# AC78xx register map
Vendor: AutoChips; Series: AC78xx; File version: 1.0
CPU: CM3 r2p1, little endian, MPU, no FPU, 3 interrupt priority bits
Registers are 32-bit, read-write, no defined reset value unless marked. A register's access mark holds for its fields unless they carry their own. Offsets are from the block's base; [hi:lo] are bit positions; {n}, {i} and the like mark numbered series; 'fields as' and 'values as' point back to an identical list.

## PWM0 — Pulse Width Management Module
Base 0x40013000; register names take the prefix PWM0_
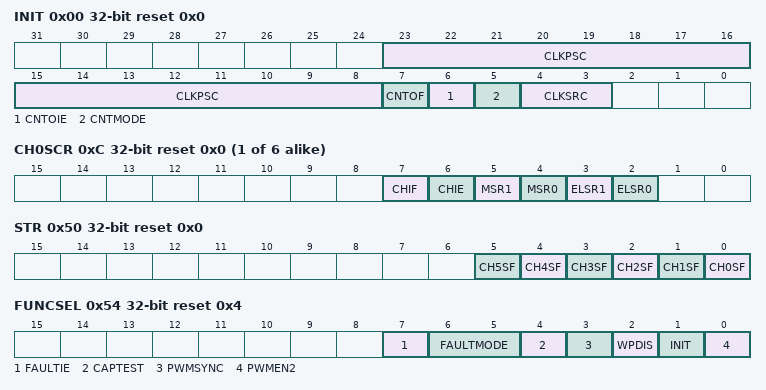
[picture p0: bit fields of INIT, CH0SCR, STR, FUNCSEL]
0x00 INIT reset 0x0 — PWM Initialize, Include Clock and Prescale Setting
  [23:8] CLKPSC — Prescale Factor Selection
  [7] CNTOF ro — PWM Counter Overflow Flag
    0=PWM counter has not overflowed; 1=PWM counter has overflowed
  [6] CNTOIE — PWM Counter Overflow Interrupt Enable
    0=Disable CNTOF interrupts. Use software polling.; 1=Enable CNTOF interrupts. An interrupt is generated when CNTOF equals one.
  [5] CNTMODE — PWM Counter Mode Select
    0=PWM counter operates in Up Counting mode; 1=PWM counter operates in Up-Down Counting mode
  [4:3] CLKSRC — Clock Source Selection
    0=No clock selected. This in effect disables the PWM counter.; 1=System clock; 2=Fixed frequency clock; 3=External clock
0x04 CNT reset 0x0 — PWM Counter Current Count Value
  [15:0] COUNT — Current Counter Value
0x08 MCVR reset 0x0 — PWM Counter Max Count Value Register
  [15:0] MCVR
{0xC+8i} CH{i}SCR (i=0..5) reset 0x0 — Channel (n) Status And Control Register
  [7] CHIF ro — Channel Interrupt Flag
    0=No channel event has occurred; 1=A channel event has occurred
  [6] CHIE — Channel Interrupt Enable
    0=Disable channel interrupts. Use software polling.; 1=Enable channel interrupts
  [5] MSR1 — Channel Mode Select Register 1
  [4] MSR0 — Channel Mode Select Register 0
  [3] ELSR1 — Edge or Level Select Register 1
  [2] ELSR0 — Edge or Level Select Register 0
{0x10+8i} CH{i}V (i=0..5) reset 0x0 — Channel (n) Value
  [15:0] CHCVAL — Channel Count Value
0x4C CNTIN reset 0x0 — Counter Initial Value
  [15:0] CNTINIT
0x50 STR reset 0x0 — Status Register
  [all] fields
    values as CH0SCR.CHIF
  [n] CH{n}SF (n=0..5) — Channel {n} Status Flag
0x54 FUNCSEL reset 0x4 — PWM Features(Functions) Mode Selection Register
  [7] FAULTIE — Fault Interrupt Enable
    0=Fault control interrupt is disabled; 1=Fault control interrupt is enabled
  [6:5] FAULTMODE — Fault Control Mode
    0=Fault control is disabled for all channels; 1=Fault control is enabled for even channels only (channels 0, 2, 4, and 6), and the selected mode is the manual fault clearing; 2=Fault control is enabled for all channels, and the selected mode is the manual fault clearing; 3=Fault control is enabled for all channels, and the selected mode is the automatic fault clearing
  [4] CAPTEST — Capture Test Mode Enable
    0=Capture test mode is disabled; 1=Capture test mode is enabled
  [3] PWMSYNC — PWM Synchronization Mode
    0=No restrictions. Software and hardware triggers can be used by MOD, CnV, OUTMASK, and PWM counter synchronization.; 1=Software trigger can only be used by MOD and CnV synchronization, and hardware triggers can only be used by OUTMASK and PWM counter synchronization
  [2] WPDIS — Write Protection Enable Register
    0=Write protection is enabled; 1=Write protection is disabled
  [1] INIT — Initialize The Channels Output
  [0] PWMEN2 — PWM Enhance function Enable
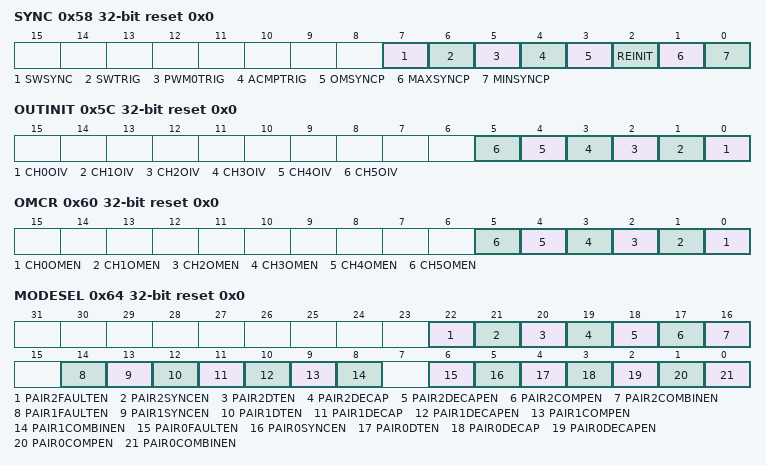
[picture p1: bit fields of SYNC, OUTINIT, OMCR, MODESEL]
0x58 SYNC reset 0x0 — Synchronization
  [7] SWSYNC — PWM Synchronization Software Trigger
    0=Software trigger is not selected; 1=Software trigger is selected
  [6] SWTRIG — PWM Synchronization Hardware Trigger 2
    0=Trigger is disabled; 1=Trigger is enabled
  [5] PWM0TRIG — PWM Synchronization Hardware Trigger 1
    0=Trigger is disabled; 1=Trigger is enabled
  [4] ACMPTRIG — PWM Synchronization Hardware Trigger 0
    0=Trigger is disabled; 1=Trigger is enabled
  [3] OMSYNCP — Output Mask Synchronization Point
    0=OUTMASK register is updated with the value of its buffer in all rising edges of the system clock; 1=OUTMASK register is updated with the value of its buffer only by the PWM synchronization
  [2] REINIT — PWM Counter Reinitialization By Synchronization (PWM counter synchronization)
    0=PWM counter continues to count normally; 1=PWM counter is updated with its initial value when the selected trigger is detected
  [1] MAXSYNCP — Maximum Loading Point Enable
    0=The maximum loading point is disabled; 1=The maximum loading point is enabled
  [0] MINSYNCP — Minimum Loading Point Enable
    0=The minimum loading point is disabled; 1=The minimum loading point is enabled
0x5C OUTINIT reset 0x0 — Initial Value For Channels Output
  [all] fields
    0=The initialization value is 0; 1=The initialization value is 1
  [n] CH{n}OIV (n=0..5) — Channel {n} Output Initialization Value
0x60 OMCR reset 0x0 — Output Mask Control Register
  [all] fields
    0=Channel output is not masked. It continues to operate normally.; 1=Channel output is masked. It is forced to its inactive state.
  [n] CH{n}OMEN (n=0..5) — Channel {n} Output Mask
0x64 MODESEL reset 0x0 — PWM Function Mode Selection
  [22] PAIR2FAULTEN — Fault Control Enable For Pair2
    0=The fault control in this pair of channels is disabled; 1=The fault control in this pair of channels is enabled
  [21] PAIR2SYNCEN — Synchronization Enable For Pair2
    0=The PWM synchronization in this pair of channels is disabled; 1=The PWM synchronization in this pair of channels is enabled
  [20] PAIR2DTEN — Deadtime Enable For Pair2
    0=The deadtime insertion in this pair of channels is disabled; 1=The deadtime insertion in this pair of channels is enabled
  [19] PAIR2DECAP — Dual Edge Capture Mode Captures For Pair2
    0=The dual edge captures are inactive; 1=The dual edge captures are active
  [18] PAIR2DECAPEN — Dual Edge Capture Mode Enable For Pair2
    0=The Dual Edge Capture mode in this pair of channels is disabled; 1=The Dual Edge Capture mode in this pair of channels is enabled
  [17] PAIR2COMPEN — Complement Of Channel (n) For Pair2
    0=The channel 5 output is the same as the channel 4 output; 1=The channel 5 output is the complement of the channel 4 output
  [16] PAIR2COMBINEN — Combine Channels For Pair2
    0=Channels 4 and 5 are independent; 1=Channels 4 and 5 are combined
  [14] PAIR1FAULTEN — Fault Control Enable For Pair1
    values as PAIR2FAULTEN
  [13] PAIR1SYNCEN — Synchronization Enable For Pair1
    values as PAIR2SYNCEN
  [12] PAIR1DTEN — Deadtime Enable For Pair1
    values as PAIR2DTEN
  [11] PAIR1DECAP — Dual Edge Capture Mode Captures For Pair1
    values as PAIR2DECAP
  [10] PAIR1DECAPEN — Dual Edge Capture Mode Enable For Pair1
    values as PAIR2DECAPEN
  [9] PAIR1COMPEN — Complement Of Channel (n) For Pair1
    0=The channel 3 output is the same as the channel 2 output; 1=The channel 3 output is the complement of the channel 2 output
  [8] PAIR1COMBINEN — Combine Channels For Pair1
    0=Channels 2 and 3 are independent; 1=Channels 2 and 3 are combined
  [6] PAIR0FAULTEN — Fault Control Enable for Pair0
    values as PAIR2FAULTEN
  [5] PAIR0SYNCEN — Synchronization Enable for Pair0
    values as PAIR2SYNCEN
  [4] PAIR0DTEN — Deadtime Enable for Pair0
    values as PAIR2DTEN
  [3] PAIR0DECAP — Dual Edge Capture Mode Captures for Pair0
    values as PAIR2DECAP
  [2] PAIR0DECAPEN — Dual Edge Capture Mode Enable for Pair0
    values as PAIR2DECAPEN
  [1] PAIR0COMPEN — Complement Channels for Pair0
    0=The channel 1 output is the same as the channel 0 output; 1=The channel 1 output is the complement of the channel 0 output
  [0] PAIR0COMBINEN — Combine Channels For Pair0
    0=Channels 0 and 1 are independent; 1=Channels 0 and 1 are combined
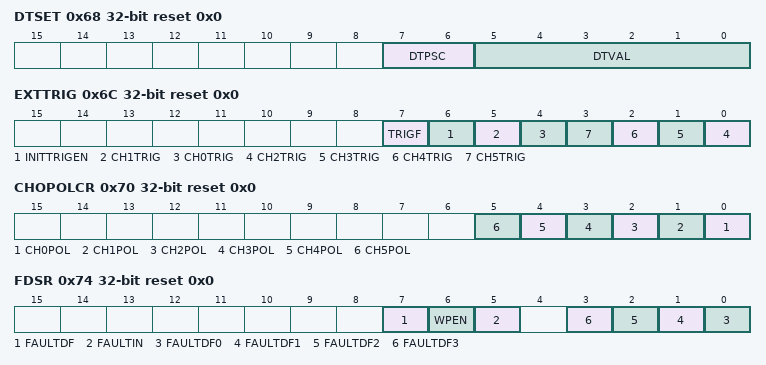
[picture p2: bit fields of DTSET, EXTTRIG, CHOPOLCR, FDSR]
0x68 DTSET reset 0x0 — Deadtime Paramenters Setting Register
  [7:6] DTPSC — Deadtime Prescaler Control Value
    0b0x=Divide the system clock by 1; 2=Divide the system clock by 4; 3=Divide the system clock by 16
  [5:0] DTVAL — Deadtime Value
0x6C EXTTRIG reset 0x0 — PWM External Trigger
  [7] TRIGF ro — Channel Trigger Flag
    0=No channel trigger was generated; 1=A channel trigger was generated
  [6] INITTRIGEN — Initialization Trigger Enable
    0=The generation of initialization trigger is disabled; 1=The generation of initialization trigger is enabled
  [5] CH1TRIG — Channel 1 Trigger Enable
    0=The generation of the channel trigger is disabled; 1=The generation of the channel trigger is enabled
  [4] CH0TRIG — Channel 0 Trigger Enable
    values as CH1TRIG
  [n-2] CH{n}TRIG (n=2..5) — Channel {n} Trigger Enable
    values as CH1TRIG
0x70 CHOPOLCR reset 0x0 — Channels Output Polarity Control Register
  [all] fields
    0=The channel polarity is active high; 1=The channel polarity is active low
  [n] CH{n}POL (n=0..5) — Channel {n} Polarity
0x74 FDSR reset 0x0 — Fault Detect Status Register
  [7] FAULTDF ro — Fault Detection Flag
    0=No fault condition was detected; 1=A fault condition was detected
  [6] WPEN — Write Protection Enable
    0=Write protection is disabled. Write protected bits can be written.; 1=Write protection is enabled. Write protected bits cannot be written.
  [5] FAULTIN ro — Fault Inputs
    0=The logic OR of the enabled fault inputs is 0; 1=The logic OR of the enabled fault inputs is 1
  [n] FAULTDF{n} ro (n=0..3) — Fault Detection Flag {n}
    0=No fault condition was detected at the fault input; 1=A fault condition was detected at the fault input
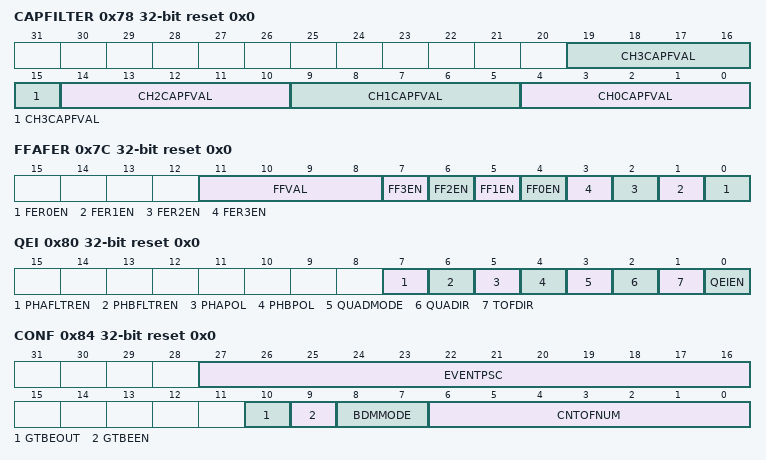
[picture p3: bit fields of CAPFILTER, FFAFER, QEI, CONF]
0x78 CAPFILTER reset 0x0 — Input Capture Filter Control
  [5n+4:5n] CH{n}CAPFVAL (n=0..3) — Channel {n} Input Filter
0x7C FFAFER reset 0x0 — Fault Filter and Fault Enable Register
  [11:8] FFVAL — Fault Input Filter
  [n+4] FF{n}EN (n=0..3) — Fault Input {n} Filter Enable
    0=Fault input filter is disabled; 1=Fault input filter is enabled
  [n] FER{n}EN (n=0..3) — Fault Input {n} Enable
    0=Fault input is disabled; 1=Fault input is enabled
0x80 QEI reset 0x0 — Quadrature Encoder/Decoder Interface Configuration Register
  [7] PHAFLTREN — Phase A Input Filter Enable Register
    0=Phase A input filter is disabled; 1=Phase A input filter is enabled
  [6] PHBFLTREN — Phase B Input Filter Enable Register
    0=Phase B input filter is disabled; 1=Phase B input filter is enabled
  [5] PHAPOL — Phase A Input Polarity
    0=Normal polarity; 1=Inverted polarity
  [4] PHBPOL — Phase B Input Polarity
    0=Normal polarity; 1=Inverted polarity
  [3] QUADMODE — Quadrature Decoder Mode
    0=Phase A and phase B encoding mode; 1=Count and direction encoding mode
  [2] QUADIR — Quadrature Decoder Mode Enable
    0=Quadrature Decoder is Disable; 1=Quadrature Decoder is Enable
  [1] TOFDIR — Timer Overflow Direction in Quadrature Decoder Mode
    0=TOF bit was set on the bottom of counting; 1=TOF bit was set on the top of counting
  [0] QEIEN — Quadrature Decoder Mode Enable
    values as QUADIR
0x84 CONF reset 0x0 — Configuration
  [27:16] EVENTPSC — PWM Channel Input Event Prescale Setting
  [10] GTBEOUT — Global Time Base Output
    0=A global time base signal generation is disabled; 1=A global time base signal generation is enabled
  [9] GTBEEN — Global Time Base Enable
    0=Use of an external global time base is disabled; 1=Use of an external global time base is enabled
  [8:7] BDMMODE — Debug Mode
  [6:0] CNTOFNUM — Count Overflow Flag Number
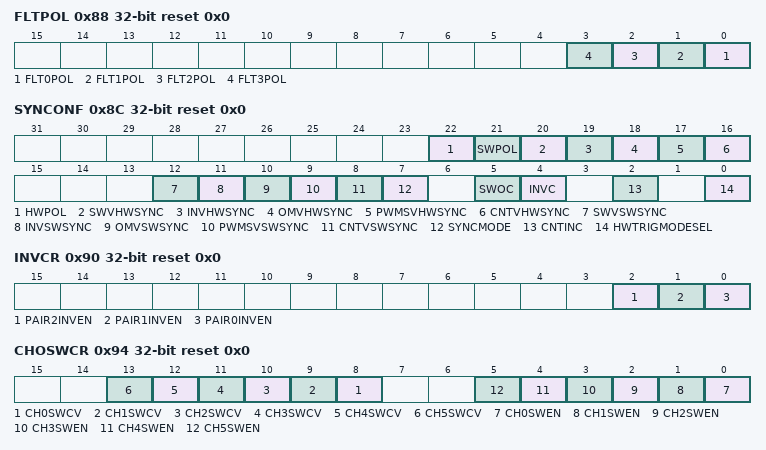
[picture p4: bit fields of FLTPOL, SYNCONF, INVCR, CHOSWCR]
0x88 FLTPOL reset 0x0 — PWM Fault Input Polarity
  [all] fields
    0=The fault input polarity is active high. A 1 at the fault input indicates a fault.; 1=The fault input polarity is active low. A 0 at the fault input indicates a fault.
  [n] FLT{n}POL (n=0..3) — Fault Input {n} Polarity
0x8C SYNCONF reset 0x0 — Synchronization Configuration
  [22] HWPOL — Channel POL synchronization is activeated by a hardwaretrigger
    0=The hardware trigger does not activate the POL register synchronization; 1=>The hardware trigger activates POL register synchronization
  [21] SWPOL — Channel POL synchronization is activeated by a softwaretrigger
    0=The software trigger does not activate the POL register synchronization; 1=The software trigger activates POL register synchronization
  [20] SWVHWSYNC
    0=A hardware trigger does not activate the SWOCTRL register synchronization; 1=A hardware trigger activates the SWOCTRL register synchronization
  [19] INVHWSYNC
    0=A hardware trigger does not activate the INVCTRL register synchronization; 1=A hardware trigger activates the INVCTRL register synchronization
  [18] OMVHWSYNC
    0=A hardware trigger does not activate the OUTMASK register synchronization; 1=A hardware trigger activates the OUTMASK register synchronization
  [17] PWMSVHWSYNC
    0=A hardware trigger does not activate MOD, CNTIN, and CV registers synchronization; 1=A hardware trigger activates MOD, CNTIN, and CV registers synchronization
  [16] CNTVHWSYNC
    0=A hardware trigger does not activate the PWM counter synchronization; 1=A hardware trigger activates the PWM counter synchronization
  [12] SWVSWSYNC
    0=The software trigger does not activate the SWOCTRL register synchronization; 1=The software trigger activates the SWOCTRL register synchronization
  [11] INVSWSYNC
    0=The software trigger does not activate the INVCTRL register synchronization; 1=The software trigger activates the INVCTRL register synchronization
  [10] OMVSWSYNC
    0=The software trigger does not activate the OUTMASK register synchronization; 1=The software trigger activates the OUTMASK register synchronization
  [9] PWMSVSWSYNC
    0=The software trigger does not activate MOD, CNTIN, and CV registers synchronization; 1=The software trigger activates MOD, CNTIN, and CV registers synchronization
  [8] CNTVSWSYNC
    0=The software trigger does not activate the PWM counter synchronization; 1=The software trigger activates the PWM counter synchronization
  [7] SYNCMODE — Synchronization Mode
    0=Legacy PWM synchronization is selected; 1=Enhanced PWM synchronization is selected
  [5] SWOC — SWOCTRL Register Synchronization
    0=SWOCTRL register is updated with its buffer value at all rising edges of system clock; 1=SWOCTRL register is updated with its buffer value by the PWM synchronization
  [4] INVC — INVCTRL Register Synchronization
    0=INVCTRL register is updated with its buffer value at all rising edges of system clock; 1=INVCTRL register is updated with its buffer value by the PWM synchronization
  [2] CNTINC — CNTIN Register Synchronization
    0=CNTIN register is updated with its buffer value at all rising edges of system clock; 1=CNTIN register is updated with its buffer value by the PWM synchronization
  [0] HWTRIGMODESEL — Hardware Trigger Mode
    0=PWM clears the TRIGj bit when the hardware trigger j is detected, where j = 0, 1,2; 1=PWM does not clear the TRIGj bit when the hardware trigger j is detected, where j = 0, 1,2
0x90 INVCR reset 0x0 — PWM Inverse Control Register
  [all] fields
    0=Inverting is disabled; 1=Inverting is enabled
  [2] PAIR2INVEN — Pair Channels 2 Inverting Enable
  [1] PAIR1INVEN — Pair Channels 1 Inverting Enable
  [0] PAIR0INVEN — Pair Channels 0 Inverting Enable
0x94 CHOSWCR reset 0x0 — PWM CHannel Software Output Control Register
  [n+8] CH{n}SWCV (n=0..5) — Channel {n} Software Output Control Value
    0=The software output control forces 0 to the channel output; 1=The software output control forces 1 to the channel output
  [n] CH{n}SWEN (n=0..5) — Channel {n} Software Output Control Enable
    0=The channel output is not affected by software output control; 1=The channel output is affected by software output control

## PWM1 — Pulse Width Management Module
Base 0x40014000; register names take the prefix PWM1_
Registers as PWM0; these are added or differ:
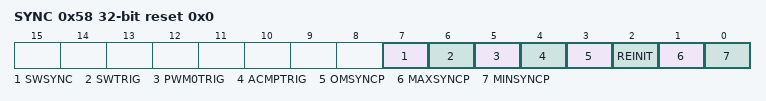
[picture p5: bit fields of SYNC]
0x58 SYNC reset 0x0 — Synchronization
  fields as PWM0.SYNC

## PWM2 — Pulse Width Management Module
Base 0x40015000; register names take the prefix PWM2_
Registers as PWM1.

## PWM3 — Pulse Width Management Module
Base 0x4001E000; register names take the prefix PWM3_
Registers as PWM1.
